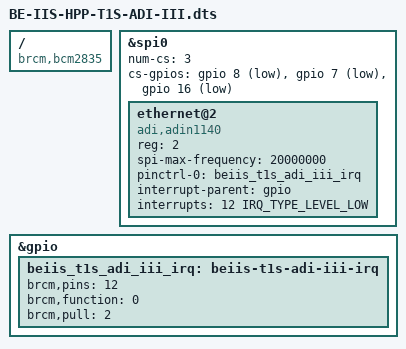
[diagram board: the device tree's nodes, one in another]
// SPDX-License-Identifier: GPL-2.0-or-later
// BE-IIS-HPP-T1S-ADI, HAT++ instance III
// SPI0 CE2: BCM GPIO16; IRQ/BUSY: BCM GPIO12
// 10BASE-T1S MAC-PHY.
// Requires SPI0 enabled. GPIO numbers are BCM, not physical header pin numbers.
/dts-v1/;
/plugin/;

#include <dt-bindings/interrupt-controller/irq.h>
#include <dt-bindings/gpio/gpio.h>

/ {
    compatible = "brcm,bcm2835", "brcm,bcm2711", "brcm,bcm2712";

    fragment@0 {
        target = <&spi0>;
        __overlay__ {
            #address-cells = <1>;
            #size-cells = <0>;
            status = "okay";
            num-cs = <3>;
            cs-gpios = <&gpio 8 GPIO_ACTIVE_LOW>,
                       <&gpio 7 GPIO_ACTIVE_LOW>,
                       <&gpio 16 GPIO_ACTIVE_LOW>;

            ethernet@2 {
                compatible = "adi,adin1140", "adi,ad3306";
                reg = <2>;
                spi-max-frequency = <20000000>;
                pinctrl-names = "default";
                pinctrl-0 = <&beiis_t1s_adi_iii_irq>;
                interrupt-parent = <&gpio>;
                interrupts = <12 IRQ_TYPE_LEVEL_LOW>;
                status = "okay";
            };
        };
    };

    fragment@2 {
        target = <&gpio>;
        __overlay__ {
            beiis_t1s_adi_iii_irq: beiis-t1s-adi-iii-irq {
                brcm,pins = <12>;
                brcm,function = <0>; /* input */
                brcm,pull = <2>; /* pull-up */
            };
        };
    };
};
